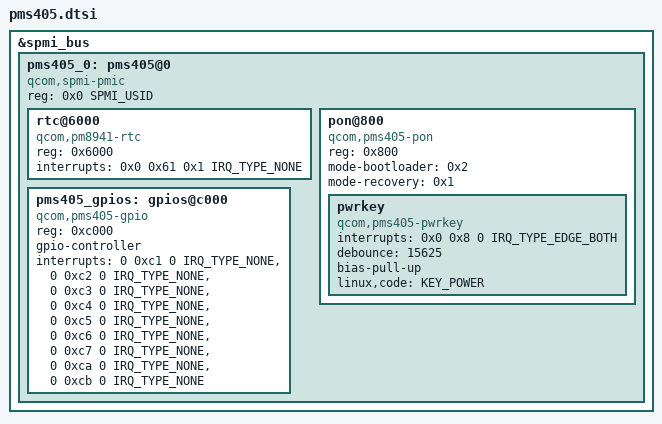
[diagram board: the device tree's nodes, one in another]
// SPDX-License-Identifier: GPL-2.0
// Copyright (c) 2018, Linaro Limited

#include <dt-bindings/spmi/spmi.h>
#include <dt-bindings/input/linux-event-codes.h>

&spmi_bus {

	pms405_0: pms405@0 {
		compatible = "qcom,spmi-pmic";
		reg = <0x0 SPMI_USID>;
		#address-cells = <1>;
		#size-cells = <0>;

		rtc@6000 {
			compatible = "qcom,pm8941-rtc";
			reg = <0x6000>;
			reg-names = "rtc", "alarm";
			interrupts = <0x0 0x61 0x1 IRQ_TYPE_NONE>;
		};

		pon@800 {
			compatible = "qcom,pms405-pon";
			reg = <0x800>;
			mode-bootloader = <0x2>;
			mode-recovery = <0x1>;

			pwrkey {
				compatible = "qcom,pms405-pwrkey";
				interrupts = <0x0 0x8 0 IRQ_TYPE_EDGE_BOTH>;
				debounce = <15625>;
				bias-pull-up;
				linux,code = <KEY_POWER>;
			};
		};

		pms405_gpios: gpios@c000 {
			compatible = "qcom,pms405-gpio";
			reg = <0xc000>;
			gpio-controller;
			#gpio-cells = <2>;
			interrupts = <0 0xc1 0 IRQ_TYPE_NONE>,
				<0 0xc2 0 IRQ_TYPE_NONE>,
				<0 0xc3 0 IRQ_TYPE_NONE>,
				<0 0xc4 0 IRQ_TYPE_NONE>,
				<0 0xc5 0 IRQ_TYPE_NONE>,
				<0 0xc6 0 IRQ_TYPE_NONE>,
				<0 0xc7 0 IRQ_TYPE_NONE>,
				<0 0xca 0 IRQ_TYPE_NONE>,
				<0 0xcb 0 IRQ_TYPE_NONE>;
		};
	};
};
